# ESP32-C3 register map
Vendor: ESPRESSIF SYSTEMS (SHANGHAI) CO., LTD.; Series: ESP32 C-Series; File version: 19
CPU: RV32IMC r0p0, little endian, no MPU, no FPU, 0 interrupt priority bits
Address unit: 32 bits
Registers are 32-bit, read-write, reset 0x0 unless marked. A register's access mark holds for its fields unless they carry their own. Offsets are from the block's base; [hi:lo] are bit positions; {n}, {i} and the like mark numbered series.

## I2C0 — I2C (Inter-Integrated Circuit) Controller 0
Base 0x60013000
0x00 SCL_LOW_PERIOD — I2C_SCL_LOW_PERIOD_REG
  [8:0] SCL_LOW_PERIOD — reg_scl_low_period
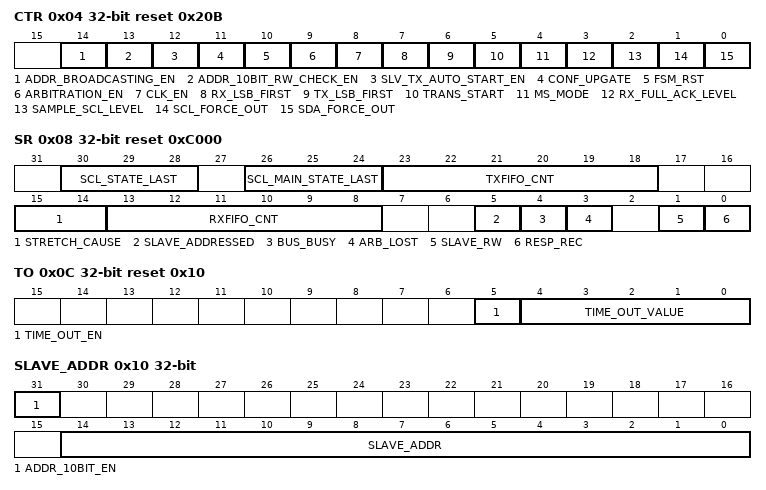
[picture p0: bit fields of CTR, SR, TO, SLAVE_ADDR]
0x04 CTR access per field reset 0x20B — I2C_CTR_REG
  [14] ADDR_BROADCASTING_EN rw — reg_addr_broadcasting_en
  [13] ADDR_10BIT_RW_CHECK_EN rw — reg_addr_10bit_rw_check_en
  [12] SLV_TX_AUTO_START_EN rw — reg_slv_tx_auto_start_en
  [11] CONF_UPGATE wo — reg_conf_upgate
  [10] FSM_RST wo — reg_fsm_rst
  [9] ARBITRATION_EN rw — reg_arbitration_en
  [8] CLK_EN rw — reg_clk_en
  [7] RX_LSB_FIRST rw — reg_rx_lsb_first
  [6] TX_LSB_FIRST rw — reg_tx_lsb_first
  [5] TRANS_START wo — reg_trans_start
  [4] MS_MODE rw — reg_ms_mode
  [3] RX_FULL_ACK_LEVEL rw — reg_rx_full_ack_level
  [2] SAMPLE_SCL_LEVEL rw — reg_sample_scl_level
  [1] SCL_FORCE_OUT rw — reg_scl_force_out
    0=Open-drain output; 1=DirectOutput
  [0] SDA_FORCE_OUT rw — reg_sda_force_out
    0=Open-drain output; 1=DirectOutput
0x08 SR ro reset 0xC000 — I2C_SR_REG
  [30:28] SCL_STATE_LAST — reg_scl_state_last
  [26:24] SCL_MAIN_STATE_LAST — reg_scl_main_state_last
  [23:18] TXFIFO_CNT — reg_txfifo_cnt
  [15:14] STRETCH_CAUSE — reg_stretch_cause
  [13:8] RXFIFO_CNT — reg_rxfifo_cnt
  [5] SLAVE_ADDRESSED — reg_slave_addressed
  [4] BUS_BUSY — reg_bus_busy
  [3] ARB_LOST — reg_arb_lost
  [1] SLAVE_RW — reg_slave_rw
  [0] RESP_REC — reg_resp_rec
0x0C TO reset 0x10 — I2C_TO_REG
  [5] TIME_OUT_EN — reg_time_out_en
  [4:0] TIME_OUT_VALUE — reg_time_out_value
0x10 SLAVE_ADDR — I2C_SLAVE_ADDR_REG
  [31] ADDR_10BIT_EN — reg_addr_10bit_en
  [14:0] SLAVE_ADDR — reg_slave_addr
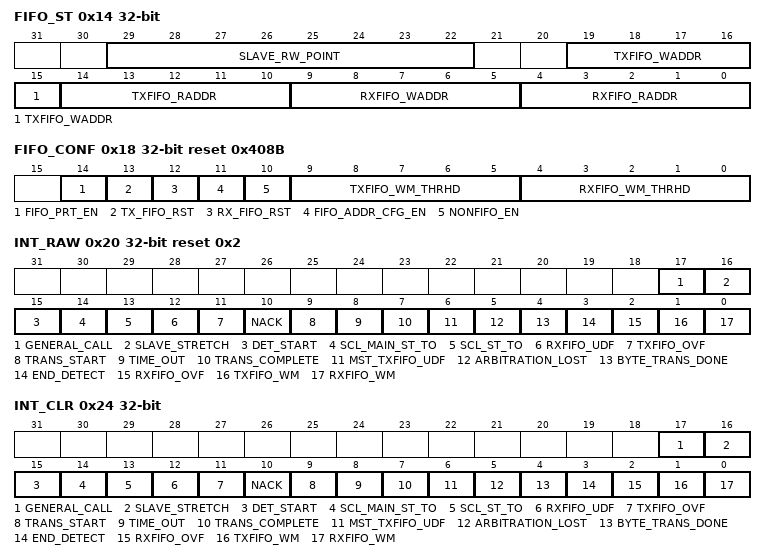
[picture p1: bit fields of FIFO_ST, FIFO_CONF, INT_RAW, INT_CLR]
0x14 FIFO_ST ro — I2C_FIFO_ST_REG
  [29:22] SLAVE_RW_POINT — reg_slave_rw_point
  [19:15] TXFIFO_WADDR — reg_txfifo_waddr
  [14:10] TXFIFO_RADDR — reg_txfifo_raddr
  [9:5] RXFIFO_WADDR — reg_rxfifo_waddr
  [4:0] RXFIFO_RADDR — reg_rxfifo_raddr
0x18 FIFO_CONF reset 0x408B — I2C_FIFO_CONF_REG
  [14] FIFO_PRT_EN — reg_fifo_prt_en
  [13] TX_FIFO_RST — reg_tx_fifo_rst
  [12] RX_FIFO_RST — reg_rx_fifo_rst
  [11] FIFO_ADDR_CFG_EN — reg_fifo_addr_cfg_en
  [10] NONFIFO_EN — reg_nonfifo_en
  [9:5] TXFIFO_WM_THRHD — reg_txfifo_wm_thrhd
  [4:0] RXFIFO_WM_THRHD — reg_rxfifo_wm_thrhd
0x1C DATA — I2C_FIFO_DATA_REG
  [7:0] FIFO_RDATA — reg_fifo_rdata
0x20 INT_RAW ro reset 0x2 — I2C_INT_RAW_REG
  [17] GENERAL_CALL — reg_general_call_int_raw
  [16] SLAVE_STRETCH — reg_slave_stretch_int_raw
  [15] DET_START — reg_det_start_int_raw
  [14] SCL_MAIN_ST_TO — reg_scl_main_st_to_int_raw
  [13] SCL_ST_TO — reg_scl_st_to_int_raw
  [12] RXFIFO_UDF — reg_rxfifo_udf_int_raw
  [11] TXFIFO_OVF — reg_txfifo_ovf_int_raw
  [10] NACK — reg_nack_int_raw
  [9] TRANS_START — reg_trans_start_int_raw
  [8] TIME_OUT — reg_time_out_int_raw
  [7] TRANS_COMPLETE — reg_trans_complete_int_raw
  [6] MST_TXFIFO_UDF — reg_mst_txfifo_udf_int_raw
  [5] ARBITRATION_LOST — reg_arbitration_lost_int_raw
  [4] BYTE_TRANS_DONE — reg_byte_trans_done_int_raw
  [3] END_DETECT — reg_end_detect_int_raw
  [2] RXFIFO_OVF — reg_rxfifo_ovf_int_raw
  [1] TXFIFO_WM — reg_txfifo_wm_int_raw
  [0] RXFIFO_WM — reg_rxfifo_wm_int_raw
0x24 INT_CLR wo — I2C_INT_CLR_REG
  [17] GENERAL_CALL write-1-clears — reg_general_call_int_clr
  [16] SLAVE_STRETCH write-1-clears — reg_slave_stretch_int_clr
  [15] DET_START write-1-clears — reg_det_start_int_clr
  [14] SCL_MAIN_ST_TO write-1-clears — reg_scl_main_st_to_int_clr
  [13] SCL_ST_TO write-1-clears — reg_scl_st_to_int_clr
  [12] RXFIFO_UDF write-1-clears — reg_rxfifo_udf_int_clr
  [11] TXFIFO_OVF write-1-clears — reg_txfifo_ovf_int_clr
  [10] NACK write-1-clears — reg_nack_int_clr
  [9] TRANS_START write-1-clears — reg_trans_start_int_clr
  [8] TIME_OUT write-1-clears — reg_time_out_int_clr
  [7] TRANS_COMPLETE write-1-clears — reg_trans_complete_int_clr
  [6] MST_TXFIFO_UDF write-1-clears — reg_mst_txfifo_udf_int_clr
  [5] ARBITRATION_LOST write-1-clears — reg_arbitration_lost_int_clr
  [4] BYTE_TRANS_DONE write-1-clears — reg_byte_trans_done_int_clr
  [3] END_DETECT write-1-clears — reg_end_detect_int_clr
  [2] RXFIFO_OVF write-1-clears — reg_rxfifo_ovf_int_clr
  [1] TXFIFO_WM write-1-clears — reg_txfifo_wm_int_clr
  [0] RXFIFO_WM write-1-clears — reg_rxfifo_wm_int_clr
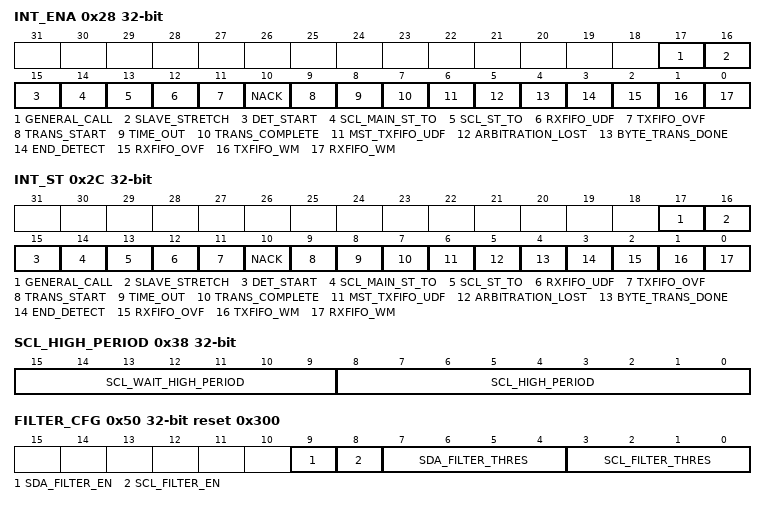
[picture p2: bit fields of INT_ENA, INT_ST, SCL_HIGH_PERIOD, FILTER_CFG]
0x28 INT_ENA — I2C_INT_ENA_REG
  [17] GENERAL_CALL — reg_general_call_int_ena
  [16] SLAVE_STRETCH — reg_slave_stretch_int_ena
  [15] DET_START — reg_det_start_int_ena
  [14] SCL_MAIN_ST_TO — reg_scl_main_st_to_int_ena
  [13] SCL_ST_TO — reg_scl_st_to_int_ena
  [12] RXFIFO_UDF — reg_rxfifo_udf_int_ena
  [11] TXFIFO_OVF — reg_txfifo_ovf_int_ena
  [10] NACK — reg_nack_int_ena
  [9] TRANS_START — reg_trans_start_int_ena
  [8] TIME_OUT — reg_time_out_int_ena
  [7] TRANS_COMPLETE — reg_trans_complete_int_ena
  [6] MST_TXFIFO_UDF — reg_mst_txfifo_udf_int_ena
  [5] ARBITRATION_LOST — reg_arbitration_lost_int_ena
  [4] BYTE_TRANS_DONE — reg_byte_trans_done_int_ena
  [3] END_DETECT — reg_end_detect_int_ena
  [2] RXFIFO_OVF — reg_rxfifo_ovf_int_ena
  [1] TXFIFO_WM — reg_txfifo_wm_int_ena
  [0] RXFIFO_WM — reg_rxfifo_wm_int_ena
0x2C INT_ST ro — I2C_INT_STATUS_REG
  [17] GENERAL_CALL — reg_general_call_int_st
  [16] SLAVE_STRETCH — reg_slave_stretch_int_st
  [15] DET_START — reg_det_start_int_st
  [14] SCL_MAIN_ST_TO — reg_scl_main_st_to_int_st
  [13] SCL_ST_TO — reg_scl_st_to_int_st
  [12] RXFIFO_UDF — reg_rxfifo_udf_int_st
  [11] TXFIFO_OVF — reg_txfifo_ovf_int_st
  [10] NACK — reg_nack_int_st
  [9] TRANS_START — reg_trans_start_int_st
  [8] TIME_OUT — reg_time_out_int_st
  [7] TRANS_COMPLETE — reg_trans_complete_int_st
  [6] MST_TXFIFO_UDF — reg_mst_txfifo_udf_int_st
  [5] ARBITRATION_LOST — reg_arbitration_lost_int_st
  [4] BYTE_TRANS_DONE — reg_byte_trans_done_int_st
  [3] END_DETECT — reg_end_detect_int_st
  [2] RXFIFO_OVF — reg_rxfifo_ovf_int_st
  [1] TXFIFO_WM — reg_txfifo_wm_int_st
  [0] RXFIFO_WM — reg_rxfifo_wm_int_st
0x30 SDA_HOLD — I2C_SDA_HOLD_REG
  [8:0] TIME — reg_sda_hold_time
0x34 SDA_SAMPLE — I2C_SDA_SAMPLE_REG
  [8:0] TIME — reg_sda_sample_time
0x38 SCL_HIGH_PERIOD — I2C_SCL_HIGH_PERIOD_REG
  [15:9] SCL_WAIT_HIGH_PERIOD — reg_scl_wait_high_period
  [8:0] SCL_HIGH_PERIOD — reg_scl_high_period
0x40 SCL_START_HOLD reset 0x8 — I2C_SCL_START_HOLD_REG
  [8:0] TIME — reg_scl_start_hold_time
0x44 SCL_RSTART_SETUP reset 0x8 — I2C_SCL_RSTART_SETUP_REG
  [8:0] TIME — reg_scl_rstart_setup_time
0x48 SCL_STOP_HOLD reset 0x8 — I2C_SCL_STOP_HOLD_REG
  [8:0] TIME — reg_scl_stop_hold_time
0x4C SCL_STOP_SETUP reset 0x8 — I2C_SCL_STOP_SETUP_REG
  [8:0] TIME — reg_scl_stop_setup_time
0x50 FILTER_CFG reset 0x300 — I2C_FILTER_CFG_REG
  [9] SDA_FILTER_EN — reg_sda_filter_en
  [8] SCL_FILTER_EN — reg_scl_filter_en
  [7:4] SDA_FILTER_THRES — reg_sda_filter_thres
  [3:0] SCL_FILTER_THRES — reg_scl_filter_thres
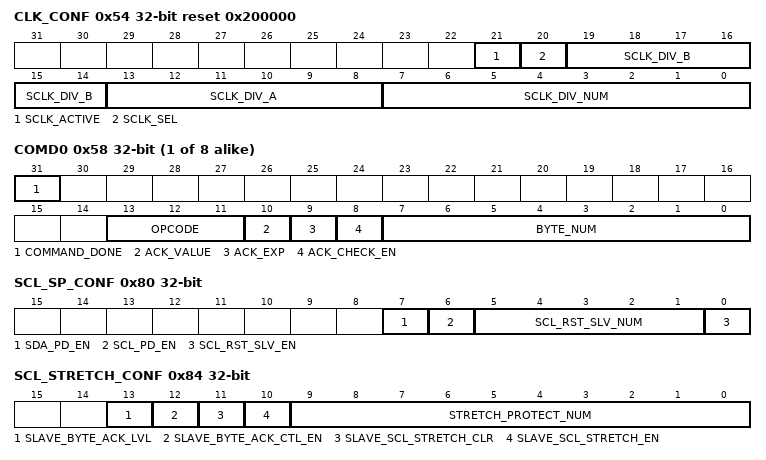
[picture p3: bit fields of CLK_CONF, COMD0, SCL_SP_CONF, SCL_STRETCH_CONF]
0x54 CLK_CONF reset 0x200000 — I2C_CLK_CONF_REG
  [21] SCLK_ACTIVE — reg_sclk_active
  [20] SCLK_SEL — reg_sclk_sel
  [19:14] SCLK_DIV_B — reg_sclk_div_b
  [13:8] SCLK_DIV_A — reg_sclk_div_a
  [7:0] SCLK_DIV_NUM — reg_sclk_div_num
{0x58+4i} COMD{i} (i=0..7) — I2C_COMD{i}_REG
  [31] COMMAND_DONE — reg_command0_done
  [13:11] OPCODE — Opcode part of command %s.
    1=WRITE opcode; 2=STOP opcode; 3=READ opcode; 4=End (END opcode); 6=RSTART opcode
  [10] ACK_VALUE — Acknowledge value for command %s.
  [9] ACK_EXP — Acknowledge expected for command %s.
  [8] ACK_CHECK_EN — Acknowledge check enable for command %s.
  [7:0] BYTE_NUM — Number of bytes to be sent or received for command %s.
0x78 SCL_ST_TIME_OUT reset 0x10 — I2C_SCL_ST_TIME_OUT_REG
  [4:0] SCL_ST_TO — reg_scl_st_to_regno more than 23
0x7C SCL_MAIN_ST_TIME_OUT reset 0x10 — I2C_SCL_MAIN_ST_TIME_OUT_REG
  [4:0] SCL_MAIN_ST_TO — reg_scl_main_st_to_regno more than 23
0x80 SCL_SP_CONF — I2C_SCL_SP_CONF_REG
  [7] SDA_PD_EN — reg_sda_pd_en
  [6] SCL_PD_EN — reg_scl_pd_en
  [5:1] SCL_RST_SLV_NUM — reg_scl_rst_slv_num
  [0] SCL_RST_SLV_EN — reg_scl_rst_slv_en
0x84 SCL_STRETCH_CONF access per field — I2C_SCL_STRETCH_CONF_REG
  [13] SLAVE_BYTE_ACK_LVL rw — reg_slave_byte_ack_lvl
  [12] SLAVE_BYTE_ACK_CTL_EN rw — reg_slave_byte_ack_ctl_en
  [11] SLAVE_SCL_STRETCH_CLR wo — reg_slave_scl_stretch_clr
  [10] SLAVE_SCL_STRETCH_EN rw — reg_slave_scl_stretch_en
  [9:0] STRETCH_PROTECT_NUM rw — reg_stretch_protect_num
0xF8 DATE — I2C_DATE_REG
0x100 TXFIFO_START_ADDR ro — I2C_TXFIFO_START_ADDR_REG
  [31:0] TXFIFO_START_ADDR — reg_txfifo_start_addr.
0x180 RXFIFO_START_ADDR ro — I2C_RXFIFO_START_ADDR_REG
  [31:0] RXFIFO_START_ADDR — reg_rxfifo_start_addr.
